# PRUSS1_ECAP_local register map
Vendor: Texas Instruments
Peripheral module from a debugger description file (folder DRA72x).
Registers are 32-bit, read-write, reset 0x0 unless marked. A register's access mark holds for its fields unless they carry their own. Offsets are as the file gives them; lines under a group give offsets from that group; [hi:lo] are bit positions; {n}, {i} and the like mark numbered series; 'fields as' and 'values as' point back to an identical list; <NAME> marks a mode.

## PRUSS1_ECAP
0x00 PRUSS_ECAP_TSCNT — Time Stamp Counter Register
  [31:0] TSCNT — Active 32 bit-counter register that is used as the capture time-base
0x04 PRUSS_ECAP_CNTPHS — Counter Phase Control Register
  [31:0] CNTPHS — Counter phase value register that can be programmed for phase lag/lead. This register shadows TSCNT and is loaded intoPRUSS_ECAP_TSCNT upon either a SYNCI event or S/W force via a control bit. Used to achieve phase control synchronization with respect to other eCAP and EPWM time-bases.
0x08 PRUSS_ECAP_CAP1 — Capture-1 Register
  [31:0] CAP1 — This register can be loaded (written) by the following. (a) Time-Stamp (that is, counter value) during a capture event. (b) Software may be useful for test purposes. (c) APRD active register when used in APWM mode.
0x0C PRUSS_ECAP_CAP2 — Capture-2 Register
  [31:0] CAP2 — This register can be loaded (written) by the following. (a) Time- Stamp (that is, counter value) during a capture event. (b) Software may be useful for test purposes. (c) APRD active register when used in APWM mode.
0x10 PRUSS_ECAP_CAP3 — Capture-3 Register
  [31:0] CAP3 — In CMP mode, this is a time-stamp capture register. In APWM mode, this is the period shadow (APRD) register. User software updates the PWM period value through this register. In this mode, CAP3 shadows CAP1.
0x14 PRUSS_ECAP_CAP4 — Capture-4 Register
  [31:0] CAP4 — In CMP mode, this is a time-stamp capture register. In APWM mode, this is the compare shadow (ACMP) register. User software updates the PWM compare value through this register. In this mode, CAP4 shadows CAP2.
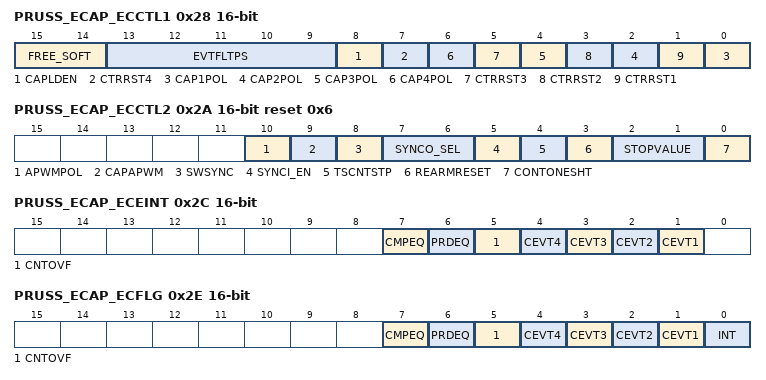
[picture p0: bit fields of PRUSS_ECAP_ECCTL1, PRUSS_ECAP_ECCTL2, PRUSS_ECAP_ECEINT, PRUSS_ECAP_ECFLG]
0x28 PRUSS_ECAP_ECCTL1 16-bit — ECAP Control Register1
  [15:14] FREE_SOFT — Emulation Control 0x0 = TSCNT counter stops immediately on emulation suspend. 0x1 = TSCNT counter runs until = 0. 0x2 = TSCNT counter is unaffected by emulation suspend (Run Free). 0x3 = TSCNT counter is unaffected by emulation suspend (Run Free).
  [13:9] EVTFLTPS — Event Filter prescale select: 0x0 = Divide by 1 (i.e,. no prescale, by-pass the prescaler) 0x1 = Divide by 2 0x2 = Divide by 4 0x3 = Divide by 6 0x4 = Divide by 8 0x5 = Divide by 10 0x1E = Divide by 60 0x1F = Divide by 62
  [8] CAPLDEN — Enable Loading ofPRUSS_ECAP_CAP1 to PRUSS_ECAP_CAP4 registers on a capture event 0x0 = Disable PRUSS_ECAP_CAP1-PRUSS_ECAP_CAP4 register loads at capture event time. 0x1 = Enable PRUSS_ECAP_CAP1-PRUSS_ECAP_CAP4 register loads at capture event time.
  [7] CTRRST4 — Counter Reset on Capture Event 4 0x0 = Do not reset counter on Capture Event 4 (absolute time stamp operation) 0x1 = Reset counter after Capture Event 4 time-stamp has been captured (used in difference mode operation)
  [2n-2] CAP{n}POL (n=1..4) — Capture Event {n} Polarity select 0x0 = Capture Event {n} triggered on a rising edge (RE) 0x1 = Capture Event {n} triggered on a falling edge (FE)
  [5] CTRRST3 — Counter Reset on Capture Event 3 0x0 = Do not reset counter on Capture Event 3 (absolute time stamp) 0x1 = Reset counter after Event 3 time-stamp has been captured (used in difference mode operation)
  [3] CTRRST2 — Counter Reset on Capture Event 2 0x0 = Do not reset counter on Capture Event 2 (absolute time stamp) 0x1 = Reset counter after Event 2 time-stamp has been captured (used in difference mode operation)
  [1] CTRRST1 — Counter Reset on Capture Event 1 0x0 = Do not reset counter on Capture Event 1 (absolute time stamp) 0x1 = Reset counter after Event 1 time-stamp has been captured (used in difference mode operation)
0x2A PRUSS_ECAP_ECCTL2 16-bit access per field reset 0x6 — ECAP Control Register 2
  [10] APWMPOL rw — APWM output polarity select. This is applicable only in APWM operating mode 0x0 = Output is active high (Compare value defines high time) 0x1 = Output is active low (Compare value defines low time)
  [9] CAPAPWM rw — CAP/APWM operating mode select 0x0 = ECAP module operates in capture mode. This mode forces the following configuration. 0x1 = ECAP module operates in APWM mode. This mode forces the following configuration.
  [8] SWSYNC rw — Software-forced Counter (TSCNT) Synchronizing. This provides a convenient software method to synchronize some or all ECAP time bases. In APWM mode, the synchronizing can also be done via the CTR = PRD event. Note: Selection CTR = PRD is meaningful only in APWM mode. However, you can choose it in CAP mode if you find doing so useful. 0x0 = Writing a zero has no effect. Reading always returns a zero 0x1 = Writing a one forces a TSCNT shadow load of current ECAP module and any ECAP modules down-stream providing the SYNCO_SEL bits are 1'b00. After writing a 1, this bit returns to a zero.
  [7:6] SYNCO_SEL rw — Sync-Out Select 0x0 = Select sync-in event to be the sync-out signal (pass through) 0x1 = Select CTR = PRD event to be the sync-out signal 0x2 = Disable sync out signal 0x3 = Disable sync out signal
  [5] SYNCI_EN rw — Counter (TSCNT) Sync-In select mode 0x0 = Disable sync-in option 0x1 = Enable counter (TSCNT) to be loaded from
  [4] TSCNTSTP rw — Time Stamp (TSCNT) Counter Stop (freeze) Control 0x0 = TSCNT stopped 0x1 = TSCNT free-running
  [3] REARMRESET rw — One-Shot Re-Arming Control, that is, wait for stop trigger. Note: The re-arm function is valid in one shot or continuous mode. 0x0 = Has no effect (reading always returns a 0) 0x1 = Arms the one-shot sequence as follows: 1) Resets the Mod4 counter to zero. 2) Unfreezes the Mod4 counter. 3) Enables capture register loads.
  [2:1] STOPVALUE rw — Stop value for one-shot mode. This is the number (between 1 and 4) of captures allowed to occur before the CAP (1 through 4) registers are frozen, that is, capture sequence is stopped. Wrap value for continuous mode. This is the number (between 1 and 4) of the capture register in which the circular buffer wraps around and starts again. Notes: STOPVALUE is compared to Mod4 counter and, when equal, the following two actions occur. (1) Mod4 counter is stopped (frozen). (2) Capture register loads are inhibited. In one-shot mode, further interrupt events are blocked until re-armed. 0x0 = Stop after Capture Event 1 in one-shot mode. Wrap after Capture Event 1 in continuous mode. 0x1 = Stop after Capture Event 2 in one-shot mode. Wrap after Capture Event 2 in continuous mode. 0x2 = Stop after Capture Event 3 in one-shot mode. Wrap after Capture Event 3 in continuous mode. 0x3 = Stop after Capture Event 4 in one-shot mode. Wrap after Capture Event 4 in continuous mode.
  [0] CONTONESHT rw — Continuous or one-shot mode control (applicable only in capture mode) 0x0 = Operate in continuous mode 0x1 = Operate in one-shot mode
0x2C PRUSS_ECAP_ECEINT 16-bit access per field — ECAP Interrupt Enable Register
  [7] CMPEQ rw — Counter Equal 0x0 = Disable Compare Equal as an Interrupt source. 0x1 = Enable Compare Equal as an Interrupt source.
  [6] PRDEQ rw — Counter Equal 0x0 = Disable Period Equal as an Interrupt source. 0x1 = Enable Period Equal as an Interrupt source.
  [5] CNTOVF rw — Counter Overflow Interrupt Enable. 0x0 = Disable counter Overflow as an Interrupt source. 0x1 = Enable counter Overflow as an Interrupt source.
  [4] CEVT4 rw — Capture Event 4 Interrupt Enable. 0x0 = Disable Capture Event 4 as an Interrupt source. 0x1 = Enable Capture Event 4 as an Interrupt source.
  [3] CEVT3 rw — Capture Event 3 Interrupt Enable. 0x0 = Disable Capture Event 3 as an Interrupt source. 0x1 = Enable Capture Event 3 as an Interrupt source.
  [2] CEVT2 rw — Capture Event 2 Interrupt Enable. 0x0 = Disable Capture Event 2 as an Interrupt source. 0x1 = Enable Capture Event 2 as an Interrupt source.
  [1] CEVT1 rw — Capture Event 1 Interrupt Enable . 0x0 = Disable Capture Event 1 as an Interrupt source. 0x1 = Enable Capture Event 1 as an Interrupt source.
0x2E PRUSS_ECAP_ECFLG 16-bit ro — ECAP Interrupt Flag Register
  [7] CMPEQ — Compare Equal Compare Status Flag. This flag is only active in APWM mode. 0x0 = Indicates no event occurred 0x1 = Indicates the counter (TSCNT) reached the compare register value (ACMP)
  [6] PRDEQ — Counter Equal Period Status Flag. This flag is only active in APWM mode. 0x0 = Indicates no event occurred 0x1 = Indicates the counter (TSCNT) reached the period register value (APRD) and was reset.
  [5] CNTOVF — Counter Overflow Status Flag. This flag is active in CAP and APWM mode. 0x0 = Indicates no event occurred. 0x1 = Indicates the counter (TSCNT) has made the transition from 0xFFFFFFFF to 0x00000000
  [4] CEVT4 — Capture Event 4 Status Flag This flag is only active in CAP mode. 0x0 = Indicates no event occurred 0x1 = Indicates the fourth event occurred at ECAPn pin
  [3] CEVT3 — Capture Event 3 Status Flag. This flag is active only in CAP mode. 0x0 = Indicates no event occurred. 0x1 = Indicates the third event occurred at ECAPn pin.
  [2] CEVT2 — Capture Event 2 Status Flag. This flag is only active in CAP mode. 0x0 = Indicates no event occurred. 0x1 = Indicates the second event occurred at ECAPn pin.
  [1] CEVT1 — Capture Event 1 Status Flag. This flag is only active in CAP mode. 0x0 = Indicates no event occurred. 0x1 = Indicates the first event occurred at ECAPn pin.
  [0] INT — Global Interrupt Status Flag 0x0 = Indicates no interrupt generated. 0x1 = Indicates that an interrupt was generated.
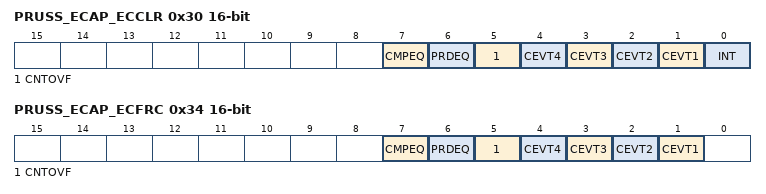
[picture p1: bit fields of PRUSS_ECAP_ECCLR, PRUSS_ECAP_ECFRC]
0x30 PRUSS_ECAP_ECCLR 16-bit access per field — ECAP Interrupt Clear Register
  [7] CMPEQ rw — Counter Equal Compare Status Flag 0x0 = Writing a 0 has no effect. Always reads back a 0 0x1 = Writing a 1 clears the CTR=CMP flag condition
  [6] PRDEQ rw — Counter Equal Period Status Flag 0x0 = Writing a 0 has no effect. Always reads back a 0 0x1 = Writing a 1 clears the CTR=PRD flag condition
  [5] CNTOVF rw — Counter Overflow Status Flag 0x0 = Writing a 0 has no effect. Always reads back a 0 0x1 = Writing a 1 clears the CNTOVF flag condition
  [4] CEVT4 rw — Capture Event 4 Status Flag 0x0 = Writing a 0 has no effect. Always reads back a 0. 0x1 = Writing a 1 clears the CEVT3 flag condition.
  [3] CEVT3 rw — Capture Event 3 Status Flag 0x0 = Writing a 0 has no effect. Always reads back a 0. 0x1 = Writing a 1 clears the CEVT3 flag condition.
  [2] CEVT2 rw — Capture Event 2 Status Flag 0x0 = Writing a 0 has no effect. Always reads back a 0. 0x1 = Writing a 1 clears the CEVT2 flag condition.
  [1] CEVT1 rw — Capture Event 1 Status Flag 0x0 = Writing a 0 has no effect. Always reads back a 0. 0x1 = Writing a 1 clears the CEVT1 flag condition.
  [0] INT rw — Global Interrupt Clear Flag 0x0 = Writing a 0 has no effect. Always reads back a 0. 0x1 = Writing a 1 clears the INT flag and enable further interrupts to be generated if any of the event flags are set to 1.
0x34 PRUSS_ECAP_ECFRC 16-bit access per field — ECAP Interrupt Forcing Register
  [7] CMPEQ rw — Force Counter Equal Compare Interrupt 0x0 = No effect. Always reads back a 0. 0x1 = Writing a 1 sets the CTR=CMP flag bit.
  [6] PRDEQ rw — Force Counter Equal Period Interrupt 0x0 = No effect. Always reads back a 0. 0x1 = Writing a 1 sets the CTR=PRD flag bit.
  [5] CNTOVF rw — Force Counter Overflow 0x0 = No effect. Always reads back a 0. 0x1 = Writing a 1 to this bit sets the CNTOVF flag bit.
  [4] CEVT4 rw — Force Capture Event 4 0x0 = No effect. Always reads back a 0. 0x1 = Writing a 1 sets the CEVT4 flag bit
  [3] CEVT3 rw — Force Capture Event 3 0x0 = No effect. Always reads back a 0. 0x1 = Writing a 1 sets the CEVT3 flag bit
  [2] CEVT2 rw — Force Capture Event 2 0x0 = No effect. Always reads back a 0. 0x1 = Writing a 1 sets the CEVT2 flag bit.
  [1] CEVT1 rw — Always reads back a 0. Force Capture Event 1 0x0 = No effect. 0x1 = Writing a 1 sets the CEVT1 flag bit.
0x5C PRUSS_ECAP_PID ro reset not defined — ECAP Revision ID
  [31:0] REVISION — IP Revision
